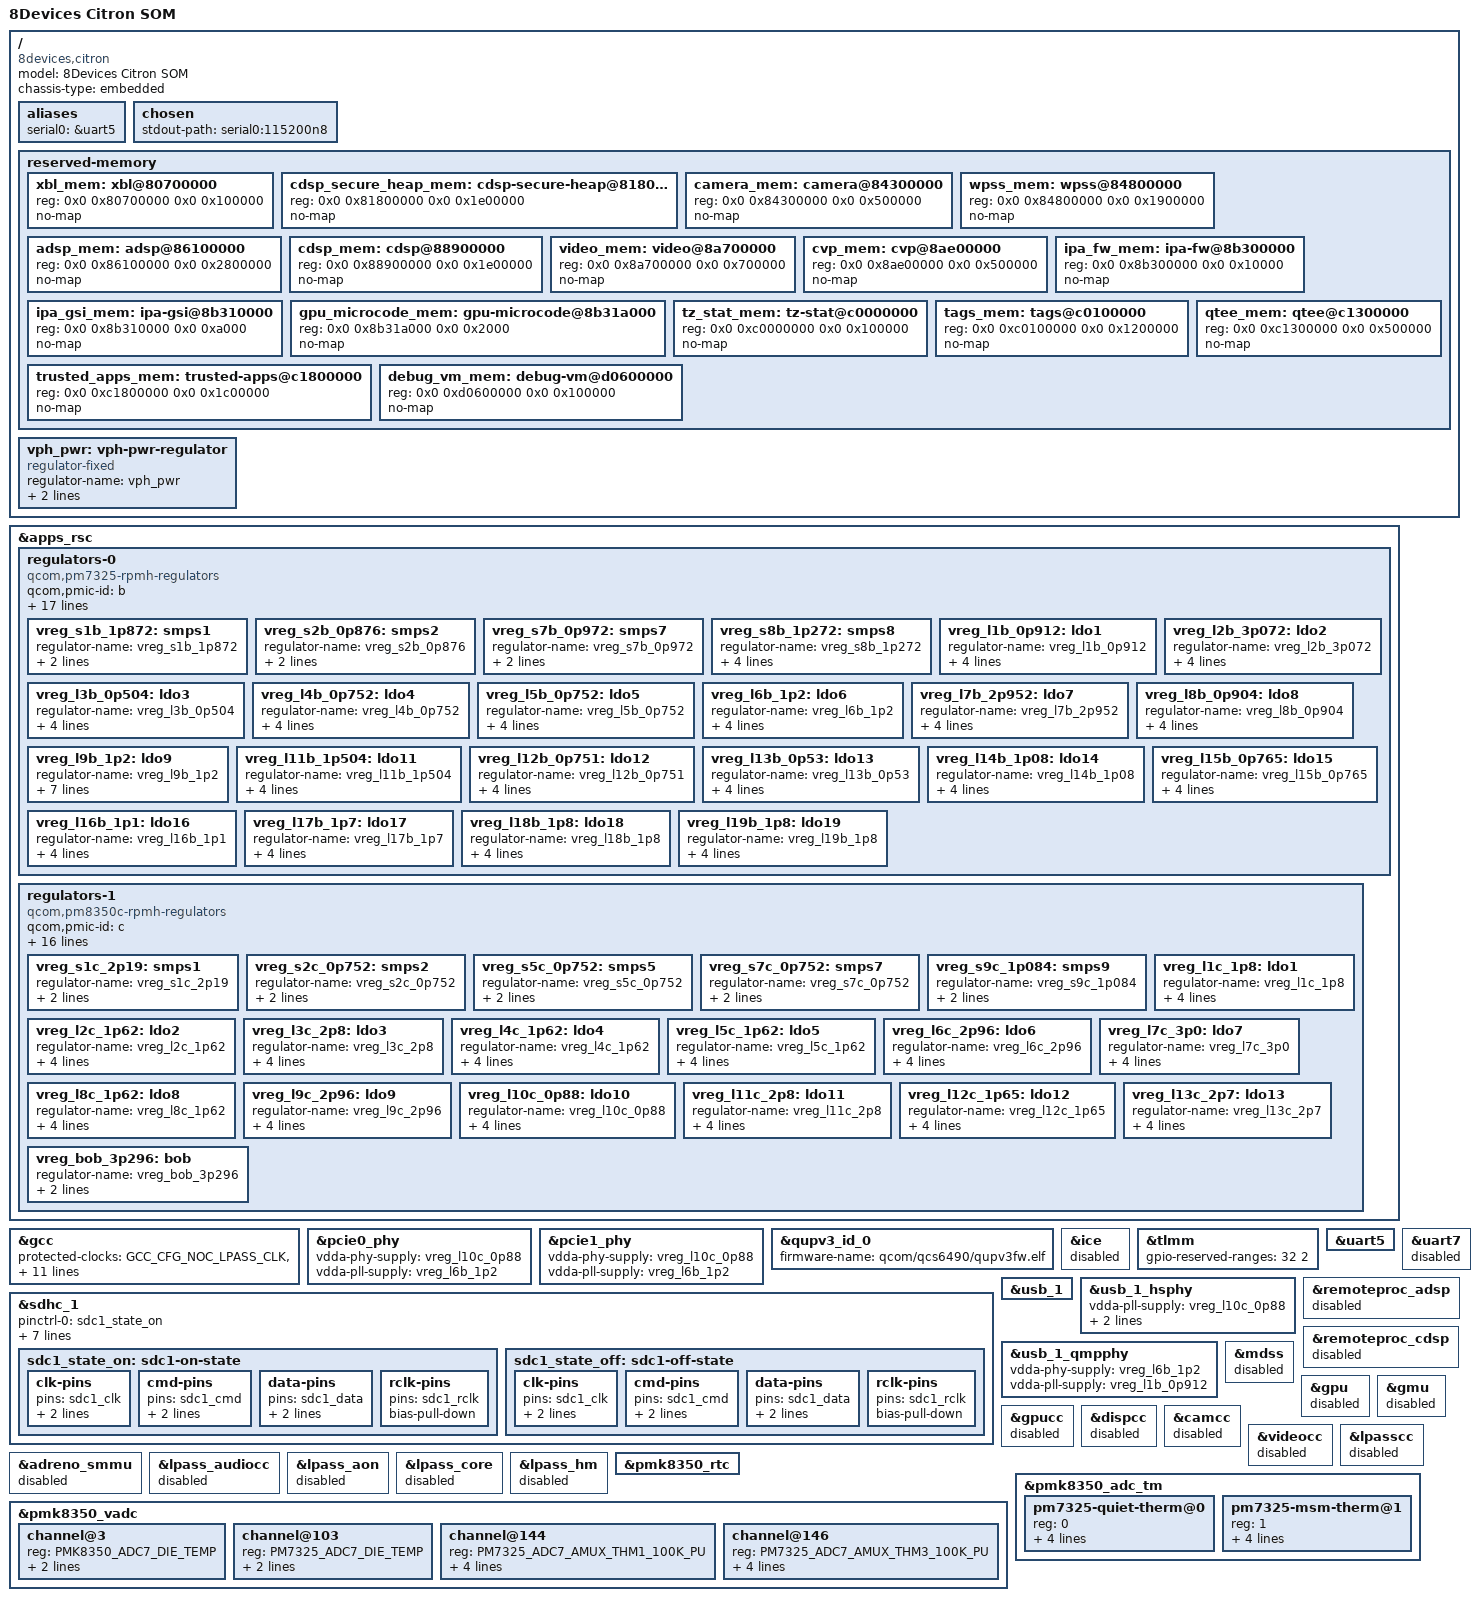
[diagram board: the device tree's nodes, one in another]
// SPDX-License-Identifier: BSD-3-Clause

/*
 * 8Devices Citron SOM - baseline device tree. Describes only what is on the SOM
 * and required to boot: QCS6490 SoC, the PM7325/PM8350C/PMK8350 PMICs and rails,
 * the DDR/firmware memory map, protected clocks, eMMC, debug UARTs and USB.
 * Everything else is left at the sc7280.dtsi defaults (disabled) for the carrier
 * board to enable.
 */

#include <dt-bindings/iio/qcom,spmi-adc7-pm7325.h>
#include <dt-bindings/iio/qcom,spmi-adc7-pmk8350.h>
#include <dt-bindings/regulator/qcom,rpmh-regulator.h>
#include "sc7280.dtsi"
#include "pm7325.dtsi"
#include "pm8350c.dtsi"
#include "pmk8350.dtsi"

/*
 * Re-base firmware/subsystem carveouts the Citron boot firmware places
 * differently from the sc7280 defaults: deleted here and re-defined below at the
 * Citron address, same label so consumers still resolve.
 * rmtfs_mem is deleted but not re-defined (modem disabled, unreferenced) to
 * reclaim its region as RAM. wlan_ce_mem is left as-is - the disabled WLAN node
 * still references it, so deleting it would dangle a phandle.
 */
/delete-node/ &ipa_fw_mem;
/delete-node/ &rmtfs_mem;
/delete-node/ &adsp_mem;
/delete-node/ &cdsp_mem;
/delete-node/ &video_mem;
/delete-node/ &wpss_mem;
/delete-node/ &xbl_mem;

/ {
	model = "8Devices Citron SOM";
	compatible = "8devices,citron", "qcom,qcm6490";
	chassis-type = "embedded";

	aliases {
		serial0 = &uart5;
	};

	chosen {
		stdout-path = "serial0:115200n8";
	};

	reserved-memory {
		xbl_mem: xbl@80700000 {
			reg = <0x0 0x80700000 0x0 0x100000>;
			no-map;
		};

		cdsp_secure_heap_mem: cdsp-secure-heap@81800000 {
			reg = <0x0 0x81800000 0x0 0x1e00000>;
			no-map;
		};

		camera_mem: camera@84300000 {
			reg = <0x0 0x84300000 0x0 0x500000>;
			no-map;
		};

		wpss_mem: wpss@84800000 {
			reg = <0x0 0x84800000 0x0 0x1900000>;
			no-map;
		};

		adsp_mem: adsp@86100000 {
			reg = <0x0 0x86100000 0x0 0x2800000>;
			no-map;
		};

		cdsp_mem: cdsp@88900000 {
			reg = <0x0 0x88900000 0x0 0x1e00000>;
			no-map;
		};

		video_mem: video@8a700000 {
			reg = <0x0 0x8a700000 0x0 0x700000>;
			no-map;
		};

		cvp_mem: cvp@8ae00000 {
			reg = <0x0 0x8ae00000 0x0 0x500000>;
			no-map;
		};

		ipa_fw_mem: ipa-fw@8b300000 {
			reg = <0x0 0x8b300000 0x0 0x10000>;
			no-map;
		};

		ipa_gsi_mem: ipa-gsi@8b310000 {
			reg = <0x0 0x8b310000 0x0 0xa000>;
			no-map;
		};

		gpu_microcode_mem: gpu-microcode@8b31a000 {
			reg = <0x0 0x8b31a000 0x0 0x2000>;
			no-map;
		};

		tz_stat_mem: tz-stat@c0000000 {
			reg = <0x0 0xc0000000 0x0 0x100000>;
			no-map;
		};

		tags_mem: tags@c0100000 {
			reg = <0x0 0xc0100000 0x0 0x1200000>;
			no-map;
		};

		qtee_mem: qtee@c1300000 {
			reg = <0x0 0xc1300000 0x0 0x500000>;
			no-map;
		};

		trusted_apps_mem: trusted-apps@c1800000 {
			reg = <0x0 0xc1800000 0x0 0x1c00000>;
			no-map;
		};

		debug_vm_mem: debug-vm@d0600000 {
			reg = <0x0 0xd0600000 0x0 0x100000>;
			no-map;
		};
	};

	vph_pwr: vph-pwr-regulator {
		compatible = "regulator-fixed";
		regulator-name = "vph_pwr";
		regulator-min-microvolt = <3700000>;
		regulator-max-microvolt = <3700000>;
	};
};

&apps_rsc {
	regulators-0 {
		compatible = "qcom,pm7325-rpmh-regulators";
		qcom,pmic-id = "b";

		vdd-s1-supply = <&vph_pwr>;
		vdd-s2-supply = <&vph_pwr>;
		vdd-s3-supply = <&vph_pwr>;
		vdd-s4-supply = <&vph_pwr>;
		vdd-s5-supply = <&vph_pwr>;
		vdd-s6-supply = <&vph_pwr>;
		vdd-s7-supply = <&vph_pwr>;
		vdd-s8-supply = <&vph_pwr>;
		vdd-l1-l4-l12-l15-supply = <&vreg_s7b_0p972>;
		vdd-l2-l7-supply = <&vreg_bob_3p296>;
		vdd-l3-supply = <&vreg_s2b_0p876>;
		vdd-l5-supply = <&vreg_s2b_0p876>;
		vdd-l6-l9-l10-supply = <&vreg_s8b_1p272>;
		vdd-l8-supply = <&vreg_s7b_0p972>;
		vdd-l11-l17-l18-l19-supply = <&vreg_s1b_1p872>;
		vdd-l13-supply = <&vreg_s7b_0p972>;
		vdd-l14-l16-supply = <&vreg_s8b_1p272>;

		vreg_s1b_1p872: smps1 {
			regulator-name = "vreg_s1b_1p872";
			regulator-min-microvolt = <1840000>;
			regulator-max-microvolt = <2040000>;
		};

		vreg_s2b_0p876: smps2 {
			regulator-name = "vreg_s2b_0p876";
			regulator-min-microvolt = <570070>;
			regulator-max-microvolt = <1050000>;
		};

		vreg_s7b_0p972: smps7 {
			regulator-name = "vreg_s7b_0p972";
			regulator-min-microvolt = <535000>;
			regulator-max-microvolt = <1120000>;
		};

		vreg_s8b_1p272: smps8 {
			regulator-name = "vreg_s8b_1p272";
			regulator-min-microvolt = <1200000>;
			regulator-max-microvolt = <1500000>;
			regulator-initial-mode = <RPMH_REGULATOR_MODE_RET>;
		};

		vreg_l1b_0p912: ldo1 {
			regulator-name = "vreg_l1b_0p912";
			regulator-min-microvolt = <825000>;
			regulator-max-microvolt = <925000>;
			regulator-initial-mode = <RPMH_REGULATOR_MODE_HPM>;
		};

		vreg_l2b_3p072: ldo2 {
			regulator-name = "vreg_l2b_3p072";
			regulator-min-microvolt = <2700000>;
			regulator-max-microvolt = <3544000>;
			regulator-initial-mode = <RPMH_REGULATOR_MODE_HPM>;
		};

		vreg_l3b_0p504: ldo3 {
			regulator-name = "vreg_l3b_0p504";
			regulator-min-microvolt = <312000>;
			regulator-max-microvolt = <910000>;
			regulator-initial-mode = <RPMH_REGULATOR_MODE_HPM>;
		};

		vreg_l4b_0p752: ldo4 {
			regulator-name = "vreg_l4b_0p752";
			regulator-min-microvolt = <752000>;
			regulator-max-microvolt = <820000>;
			regulator-initial-mode = <RPMH_REGULATOR_MODE_HPM>;
		};

		vreg_l5b_0p752: ldo5 {
			regulator-name = "vreg_l5b_0p752";
			regulator-min-microvolt = <552000>;
			regulator-max-microvolt = <832000>;
			regulator-initial-mode = <RPMH_REGULATOR_MODE_HPM>;
		};

		vreg_l6b_1p2: ldo6 {
			regulator-name = "vreg_l6b_1p2";
			regulator-min-microvolt = <1140000>;
			regulator-max-microvolt = <1260000>;
			regulator-initial-mode = <RPMH_REGULATOR_MODE_HPM>;
		};

		vreg_l7b_2p952: ldo7 {
			regulator-name = "vreg_l7b_2p952";
			regulator-min-microvolt = <2952000>;
			regulator-max-microvolt = <2952000>;
			regulator-initial-mode = <RPMH_REGULATOR_MODE_HPM>;
		};

		vreg_l8b_0p904: ldo8 {
			regulator-name = "vreg_l8b_0p904";
			regulator-min-microvolt = <870000>;
			regulator-max-microvolt = <970000>;
			regulator-initial-mode = <RPMH_REGULATOR_MODE_HPM>;
		};

		vreg_l9b_1p2: ldo9 {
			regulator-name = "vreg_l9b_1p2";
			regulator-min-microvolt = <1200000>;
			regulator-max-microvolt = <1200000>;
			regulator-initial-mode = <RPMH_REGULATOR_MODE_HPM>;
			regulator-allow-set-load;
			regulator-allowed-modes = <RPMH_REGULATOR_MODE_LPM
						   RPMH_REGULATOR_MODE_HPM>;
		};

		vreg_l11b_1p504: ldo11 {
			regulator-name = "vreg_l11b_1p504";
			regulator-min-microvolt = <1504000>;
			regulator-max-microvolt = <2000000>;
			regulator-initial-mode = <RPMH_REGULATOR_MODE_HPM>;
		};

		vreg_l12b_0p751: ldo12 {
			regulator-name = "vreg_l12b_0p751";
			regulator-min-microvolt = <751000>;
			regulator-max-microvolt = <824000>;
			regulator-initial-mode = <RPMH_REGULATOR_MODE_HPM>;
		};

		vreg_l13b_0p53: ldo13 {
			regulator-name = "vreg_l13b_0p53";
			regulator-min-microvolt = <530000>;
			regulator-max-microvolt = <824000>;
			regulator-initial-mode = <RPMH_REGULATOR_MODE_HPM>;
		};

		vreg_l14b_1p08: ldo14 {
			regulator-name = "vreg_l14b_1p08";
			regulator-min-microvolt = <1080000>;
			regulator-max-microvolt = <1304000>;
			regulator-initial-mode = <RPMH_REGULATOR_MODE_HPM>;
		};

		vreg_l15b_0p765: ldo15 {
			regulator-name = "vreg_l15b_0p765";
			regulator-min-microvolt = <765000>;
			regulator-max-microvolt = <1020000>;
			regulator-initial-mode = <RPMH_REGULATOR_MODE_HPM>;
		};

		vreg_l16b_1p1: ldo16 {
			regulator-name = "vreg_l16b_1p1";
			regulator-min-microvolt = <1100000>;
			regulator-max-microvolt = <1300000>;
			regulator-initial-mode = <RPMH_REGULATOR_MODE_HPM>;
		};

		vreg_l17b_1p7: ldo17 {
			regulator-name = "vreg_l17b_1p7";
			regulator-min-microvolt = <1700000>;
			regulator-max-microvolt = <1900000>;
			regulator-initial-mode = <RPMH_REGULATOR_MODE_HPM>;
		};

		vreg_l18b_1p8: ldo18 {
			regulator-name = "vreg_l18b_1p8";
			regulator-min-microvolt = <1800000>;
			regulator-max-microvolt = <2000000>;
			regulator-initial-mode = <RPMH_REGULATOR_MODE_HPM>;
		};

		vreg_l19b_1p8: ldo19 {
			regulator-name = "vreg_l19b_1p8";
			regulator-min-microvolt = <1800000>;
			regulator-max-microvolt = <2000000>;
			regulator-initial-mode = <RPMH_REGULATOR_MODE_HPM>;
		};
	};

	regulators-1 {
		compatible = "qcom,pm8350c-rpmh-regulators";
		qcom,pmic-id = "c";

		vdd-s1-supply = <&vph_pwr>;
		vdd-s2-supply = <&vph_pwr>;
		vdd-s3-supply = <&vph_pwr>;
		vdd-s4-supply = <&vph_pwr>;
		vdd-s5-supply = <&vph_pwr>;
		vdd-s6-supply = <&vph_pwr>;
		vdd-s7-supply = <&vph_pwr>;
		vdd-s8-supply = <&vph_pwr>;
		vdd-s9-supply = <&vph_pwr>;
		vdd-s10-supply = <&vph_pwr>;
		vdd-l1-l12-supply = <&vreg_s1b_1p872>;
		vdd-l2-l8-supply = <&vreg_s1b_1p872>;
		vdd-l3-l4-l5-l7-l13-supply = <&vreg_bob_3p296>;
		vdd-l6-l9-l11-supply = <&vreg_bob_3p296>;
		vdd-l10-supply = <&vreg_s7b_0p972>;
		vdd-bob-supply = <&vph_pwr>;

		vreg_s1c_2p19: smps1 {
			regulator-name = "vreg_s1c_2p19";
			regulator-min-microvolt = <2190000>;
			regulator-max-microvolt = <2210000>;
		};

		vreg_s2c_0p752: smps2 {
			regulator-name = "vreg_s2c_0p752";
			regulator-min-microvolt = <750000>;
			regulator-max-microvolt = <800000>;
		};

		vreg_s5c_0p752: smps5 {
			regulator-name = "vreg_s5c_0p752";
			regulator-min-microvolt = <465000>;
			regulator-max-microvolt = <1050000>;
		};

		vreg_s7c_0p752: smps7 {
			regulator-name = "vreg_s7c_0p752";
			regulator-min-microvolt = <465000>;
			regulator-max-microvolt = <800000>;
		};

		vreg_s9c_1p084: smps9 {
			regulator-name = "vreg_s9c_1p084";
			regulator-min-microvolt = <1010000>;
			regulator-max-microvolt = <1170000>;
		};

		vreg_l1c_1p8: ldo1 {
			regulator-name = "vreg_l1c_1p8";
			regulator-min-microvolt = <1800000>;
			regulator-max-microvolt = <1980000>;
			regulator-initial-mode = <RPMH_REGULATOR_MODE_HPM>;
		};

		vreg_l2c_1p62: ldo2 {
			regulator-name = "vreg_l2c_1p62";
			regulator-min-microvolt = <1620000>;
			regulator-max-microvolt = <1980000>;
			regulator-initial-mode = <RPMH_REGULATOR_MODE_HPM>;
		};

		vreg_l3c_2p8: ldo3 {
			regulator-name = "vreg_l3c_2p8";
			regulator-min-microvolt = <2800000>;
			regulator-max-microvolt = <3540000>;
			regulator-initial-mode = <RPMH_REGULATOR_MODE_HPM>;
		};

		vreg_l4c_1p62: ldo4 {
			regulator-name = "vreg_l4c_1p62";
			regulator-min-microvolt = <1620000>;
			regulator-max-microvolt = <3300000>;
			regulator-initial-mode = <RPMH_REGULATOR_MODE_HPM>;
		};

		vreg_l5c_1p62: ldo5 {
			regulator-name = "vreg_l5c_1p62";
			regulator-min-microvolt = <1620000>;
			regulator-max-microvolt = <3300000>;
			regulator-initial-mode = <RPMH_REGULATOR_MODE_HPM>;
		};

		vreg_l6c_2p96: ldo6 {
			regulator-name = "vreg_l6c_2p96";
			regulator-min-microvolt = <1650000>;
			regulator-max-microvolt = <3544000>;
			regulator-initial-mode = <RPMH_REGULATOR_MODE_HPM>;
		};

		vreg_l7c_3p0: ldo7 {
			regulator-name = "vreg_l7c_3p0";
			regulator-min-microvolt = <3000000>;
			regulator-max-microvolt = <3544000>;
			regulator-initial-mode = <RPMH_REGULATOR_MODE_HPM>;
		};

		vreg_l8c_1p62: ldo8 {
			regulator-name = "vreg_l8c_1p62";
			regulator-min-microvolt = <1620000>;
			regulator-max-microvolt = <2000000>;
			regulator-initial-mode = <RPMH_REGULATOR_MODE_HPM>;
		};

		vreg_l9c_2p96: ldo9 {
			regulator-name = "vreg_l9c_2p96";
			regulator-min-microvolt = <2700000>;
			regulator-max-microvolt = <3544000>;
			regulator-initial-mode = <RPMH_REGULATOR_MODE_HPM>;
		};

		vreg_l10c_0p88: ldo10 {
			regulator-name = "vreg_l10c_0p88";
			regulator-min-microvolt = <720000>;
			regulator-max-microvolt = <1050000>;
			regulator-initial-mode = <RPMH_REGULATOR_MODE_HPM>;
		};

		vreg_l11c_2p8: ldo11 {
			regulator-name = "vreg_l11c_2p8";
			regulator-min-microvolt = <2800000>;
			regulator-max-microvolt = <3544000>;
			regulator-initial-mode = <RPMH_REGULATOR_MODE_HPM>;
		};

		vreg_l12c_1p65: ldo12 {
			regulator-name = "vreg_l12c_1p65";
			regulator-min-microvolt = <1650000>;
			regulator-max-microvolt = <2000000>;
			regulator-initial-mode = <RPMH_REGULATOR_MODE_HPM>;
		};

		vreg_l13c_2p7: ldo13 {
			regulator-name = "vreg_l13c_2p7";
			regulator-min-microvolt = <2700000>;
			regulator-max-microvolt = <3544000>;
			regulator-initial-mode = <RPMH_REGULATOR_MODE_HPM>;
		};

		vreg_bob_3p296: bob {
			regulator-name = "vreg_bob_3p296";
			regulator-min-microvolt = <3008000>;
			regulator-max-microvolt = <3960000>;
		};
	};
};

&gcc {
	protected-clocks = <GCC_CFG_NOC_LPASS_CLK>,
			   <GCC_MSS_CFG_AHB_CLK>,
			   <GCC_MSS_GPLL0_MAIN_DIV_CLK_SRC>,
			   <GCC_MSS_OFFLINE_AXI_CLK>,
			   <GCC_MSS_Q6SS_BOOT_CLK_SRC>,
			   <GCC_MSS_Q6_MEMNOC_AXI_CLK>,
			   <GCC_MSS_SNOC_AXI_CLK>,
			   <GCC_QSPI_CNOC_PERIPH_AHB_CLK>,
			   <GCC_QSPI_CORE_CLK>,
			   <GCC_QSPI_CORE_CLK_SRC>,
			   <GCC_SEC_CTRL_CLK_SRC>,
			   <GCC_WPSS_AHB_BDG_MST_CLK>,
			   <GCC_WPSS_AHB_CLK>,
			   <GCC_WPSS_RSCP_CLK>;
};

/*
 * PCIe PHYs - on-module SoC blocks on on-module PMIC rails, enabled here. The
 * controllers (&pcie0/&pcie1) stay disabled: each needs the carrier's PERST GPIO
 * and a downstream endpoint, and enabling one without those hangs the bus at
 * probe. A PHY is inert until a carrier enables its controller, so enabling both
 * is harmless. Both share the same vdda-phy/vdda-pll rails.
 */
&pcie0_phy {
	vdda-phy-supply = <&vreg_l10c_0p88>;
	vdda-pll-supply = <&vreg_l6b_1p2>;
	status = "okay";
};

&pcie1_phy {
	vdda-phy-supply = <&vreg_l10c_0p88>;
	vdda-pll-supply = <&vreg_l6b_1p2>;
	status = "okay";
};

&qupv3_id_0 {
	firmware-name = "qcom/qcs6490/qupv3fw.elf";
	status = "okay";
};

/*
 * The inline crypto engine (sc7280 crypto@1d88000) is owned by the secure side
 * on this platform; reading its registers from the Linux VM triggers an
 * asynchronous SError in qcom_ice_create during probe (kernel panic). Disable
 * it - the eMMC below does not use inline hardware crypto (qcom,ice deleted).
 */
&ice {
	status = "disabled";
};

/* On-SOM 32 GB eMMC. */
&sdhc_1 {
	pinctrl-0 = <&sdc1_state_on>;
	pinctrl-1 = <&sdc1_state_off>;
	pinctrl-names = "default", "sleep";

	vmmc-supply = <&vreg_l7b_2p952>;
	vqmmc-supply = <&vreg_l19b_1p8>;
	no-sdio;
	non-removable;
	no-sd;
	supports-cqe;

	/* ICE is disabled (see &ice above) - don't reference it. */
	/delete-property/ qcom,ice;

	status = "okay";

	sdc1_state_on: sdc1-on-state {
		clk-pins {
			pins = "sdc1_clk";
			drive-strength = <16>;
			bias-disable;
		};

		cmd-pins {
			pins = "sdc1_cmd";
			drive-strength = <10>;
			bias-pull-up;
		};

		data-pins {
			pins = "sdc1_data";
			drive-strength = <10>;
			bias-pull-up;
		};

		rclk-pins {
			pins = "sdc1_rclk";
			bias-pull-down;
		};
	};

	sdc1_state_off: sdc1-off-state {
		clk-pins {
			pins = "sdc1_clk";
			drive-strength = <2>;
			bias-disable;
		};

		cmd-pins {
			pins = "sdc1_cmd";
			drive-strength = <2>;
			bias-pull-up;
		};

		data-pins {
			pins = "sdc1_data";
			drive-strength = <2>;
			bias-pull-up;
		};

		rclk-pins {
			pins = "sdc1_rclk";
			bias-pull-down;
		};
	};
};

&tlmm {
	/*
	 * GPIOs owned by firmware - the HLOS must not touch them or pinctrl-msm hangs
	 * at gpiochip bringup. Must match the XBL/TZ GPIO-ownership config.
	 * Only the ADSP pins (32-33) are reserved; gpio48-51 are left free for uart12,
	 * which REQUIRES a matching XBL/TZ change releasing them - without it the board
	 * hangs at gpiochip bringup.
	 */
	gpio-reserved-ranges = <32 2>;	/* ADSP (gpio48-51 freed for uart12 - needs XBL release) */
};

&uart5 {
	status = "okay";
};

/*
 * uart7 (QUP0 SE7, GPIO28-31) left disabled: the carrier repurposes those pins,
 * so the SOM must not claim them for a UART.
 */
&uart7 {
	status = "disabled";
};

/*
 * USB1 (usb_1) - SuperSpeed controller + HS and USB3/DP combo PHYs, on-module
 * SoC blocks on on-module rails, enabled here. The data role, Type-C and VBUS
 * switching are carrier wiring. orientation-switch is left at the sc7280 default
 * for the carrier to keep or delete.
 */
&usb_1 {
	status = "okay";
};

&usb_1_hsphy {
	vdda-pll-supply = <&vreg_l10c_0p88>;
	vdda33-supply = <&vreg_l2b_3p072>;
	vdda18-supply = <&vreg_l1c_1p8>;
	status = "okay";
};

&usb_1_qmpphy {
	vdda-phy-supply = <&vreg_l6b_1p2>;
	vdda-pll-supply = <&vreg_l1b_0p912>;
	status = "okay";
};

/*
 * aDSP and cDSP remote processors - disabled. Headless networking board: no
 * audio (aDSP) and no NPU/compute offload (cDSP). The rest of the DSP stack
 * (remoteproc, pd-mapper, fastrpc, adsp/cdsp.mbn) is removed in minimize.cfg and
 * the firmware/image config. Modem and WLAN remoteprocs were already disabled.
 */
&remoteproc_adsp {
	status = "disabled";
};

&remoteproc_cdsp {
	status = "disabled";
};

/*
 * Disable on-die multimedia (MDSS display, Adreno GPU + GMU): headless board,
 * their kernel drivers (DRM/MSM) are removed, so the nodes would be driverless.
 */
&mdss {
	status = "disabled";
};

&gpu {
	status = "disabled";
};

&gmu {
	status = "disabled";
};

/*
 * Disable the GPU/display/camera/video clock controllers and GPU SMMU. Their
 * drivers are off (minimize.cfg) but the nodes are enabled-by-default in
 * sc7280.dtsi; left driverless they block gcc-sc7280 sync_state() and time out
 * the adreno SMMU probe (-110). Their only consumers are already disabled.
 */
&gpucc {
	status = "disabled";
};

&dispcc {
	status = "disabled";
};

&camcc {
	status = "disabled";
};

&videocc {
	status = "disabled";
};

&adreno_smmu {
	status = "disabled";
};

/*
 * LPASS audio clock controllers - no audio on this board. Their consumers (codec
 * macros + DAIs) are already disabled in sc7280.dtsi, so disabling these
 * providers completes the audio teardown.
 */
&lpasscc {
	status = "disabled";
};

&lpass_audiocc {
	status = "disabled";
};

&lpass_aon {
	status = "disabled";
};

&lpass_core {
	status = "disabled";
};

&lpass_hm {
	status = "disabled";
};

/*
 * RTC inside the PMK8350 PMIC (on SPMI) - SOM PMIC, no carrier wiring, enabled
 * here. Note it only keeps time while the PMIC is powered (VPH_PWR); without a
 * backup supply the wall clock won't persist across full power-off.
 */
&pmk8350_rtc {
	status = "okay";
};

/*
 * PMIC ADC (PMK8350 ADC7 master, muxing PMK8350 + PM7325 AMUX inputs). Needs at
 * least one channel or it probes -EINVAL. Channels: two board thermistors (TDK
 * NTCG064EF104FT 100k, stock _100K_PU curve) on PM7325 THM1/THM3, plus the two
 * PMIC die-temp channels.
 */
&pmk8350_vadc {
	channel@3 {
		reg = <PMK8350_ADC7_DIE_TEMP>;
		label = "pmk8350_die_temp";
		qcom,pre-scaling = <1 1>;
	};

	channel@103 {
		reg = <PM7325_ADC7_DIE_TEMP>;
		label = "pm7325_die_temp";
		qcom,pre-scaling = <1 1>;
	};

	channel@144 {
		reg = <PM7325_ADC7_AMUX_THM1_100K_PU>;
		label = "pm7325_quiet_therm";
		qcom,ratiometric;
		qcom,hw-settle-time = <200>;
		qcom,pre-scaling = <1 1>;
	};

	channel@146 {
		reg = <PM7325_ADC7_AMUX_THM3_100K_PU>;
		label = "pm7325_msm_therm";
		qcom,ratiometric;
		qcom,hw-settle-time = <200>;
		qcom,pre-scaling = <1 1>;
	};
};

/*
 * ADC thermal monitor - registers the two board thermistors as thermal sensors
 * so thermal zones can consume them. Makes them readable; automatic throttling
 * still needs a thermal-zone with trips + cooling-maps.
 */
&pmk8350_adc_tm {
	status = "okay";

	pm7325-quiet-therm@0 {
		reg = <0>;
		io-channels = <&pmk8350_vadc PM7325_ADC7_AMUX_THM1_100K_PU>;
		qcom,ratiometric;
		qcom,hw-settle-time-us = <200>;
	};

	pm7325-msm-therm@1 {
		reg = <1>;
		io-channels = <&pmk8350_vadc PM7325_ADC7_AMUX_THM3_100K_PU>;
		qcom,ratiometric;
		qcom,hw-settle-time-us = <200>;
	};
};
